# CW32L012 register map
Vendor: Wuhan Xinyuan Semiconductor Co.Ltd; Series: ARMCM0P; File version: 1.2
CPU: CM0+ r0p1, little endian, no MPU, no FPU, VTOR, 2 interrupt priority bits
Registers are 32-bit, read-write, no defined reset value unless marked. A register's access mark holds for its fields unless they carry their own. Offsets are from the block's base; [hi:lo] are bit positions; {n}, {i} and the like mark numbered series.

## BTIM1 — Base Timer 1
Base 0x40004800
Same registers: BTIM2 0x40004840, BTIM3 0x40004880
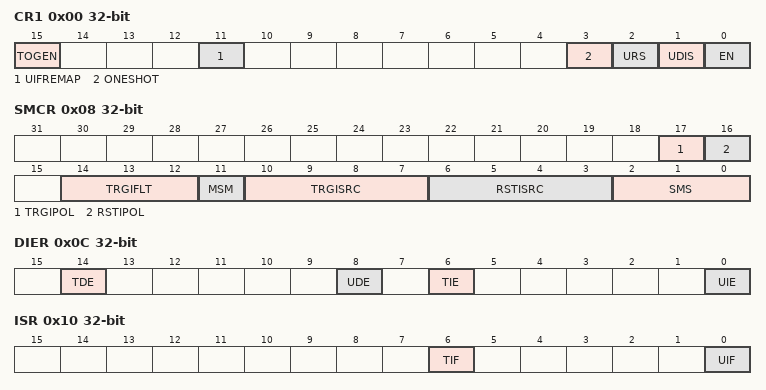
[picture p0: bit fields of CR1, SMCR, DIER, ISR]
0x00 CR1 — Control register1
  [15] TOGEN, [11] UIFREMAP, [3] ONESHOT, [2] URS, [1] UDIS, [0] EN
0x04 CR2 — Control register2
  [6:4] MMS
0x08 SMCR — Slave Mode Control register
  [17] TRGIPOL, [16] RSTIPOL, [14:12] TRGIFLT, [11] MSM, [10:7] TRGISRC, [6:3] RSTISRC, [2:0] SMS
0x0C DIER — Interrupt enable register
  [14] TDE, [8] UDE, [6] TIE, [0] UIE
0x10 ISR ro — Interrupt status register
  [6] TIF, [0] UIF
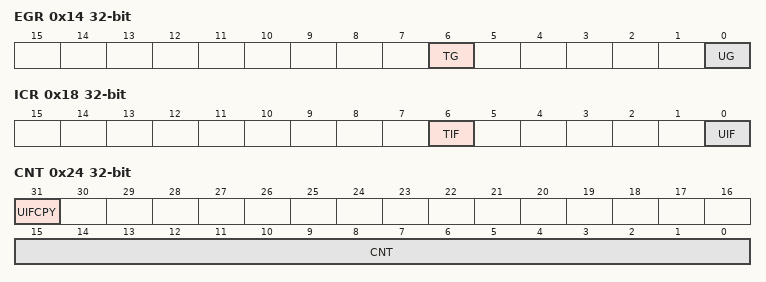
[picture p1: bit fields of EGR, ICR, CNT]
0x14 EGR wo — Event Generate register
  [6] TG, [0] UG
0x18 ICR — Interrupt flag clear register
  [6] TIF, [0] UIF
0x24 CNT — Counter Register
  [31] UIFCPY ro, [15:0] CNT
0x28 PSC — Prescaler Control Register
  [15:0] PSC
0x2C ARR — Auto Reload Register
  [15:0] ARR

## CORDIC
Base 0x40023400
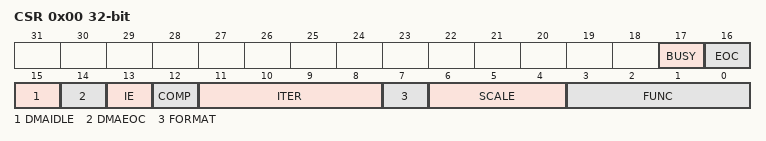
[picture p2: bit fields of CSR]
0x00 CSR — Control and State register
  [17] BUSY ro, [16] EOC ro, [15] DMAIDLE, [14] DMAEOC, [13] IE, [12] COMP, [11:8] ITER, [7] FORMAT, [6:4] SCALE, [3:0] FUNC
0x04 X — Data register X
0x08 Y — Data register Y
0x0C Z

## CRC
Base 0x40023000
0x00 CR — Control register
  [3:0] MODE
0x08 DR — Data register
  [7:0] DR
0x0C RESULT ro
  [15:0] RESULT

## DAC
Base 0x400000C0
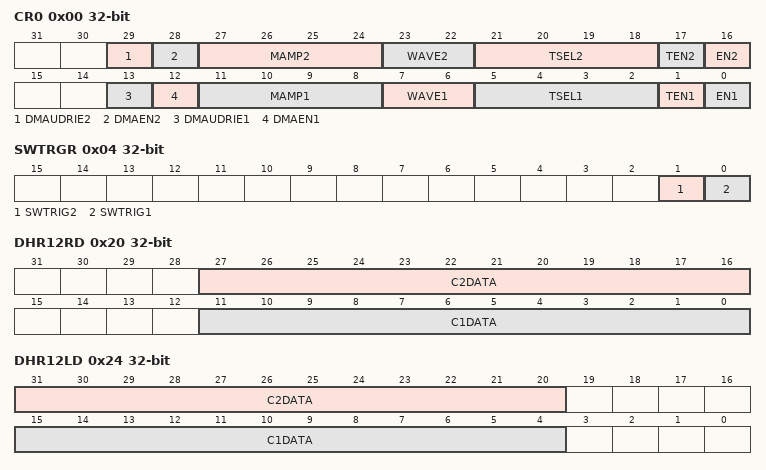
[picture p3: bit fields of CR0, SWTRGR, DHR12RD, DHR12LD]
0x00 CR0 — Control register
  [29] DMAUDRIE2, [28] DMAEN2, [27:24] MAMP2, [23:22] WAVE2, [21:18] TSEL2, [17] TEN2, [16] EN2, [13] DMAUDRIE1, [12] DMAEN1, [11:8] MAMP1, [7:6] WAVE1, [5:2] TSEL1, [1] TEN1, [0] EN1
0x04 SWTRGR — Data register
  [1] SWTRIG2, [0] SWTRIG1
0x08 DHR12R1
  [11:0] DATA
0x0C DHR12L1
  [15:4] DATA
0x10 DHR8R1
  [7:0] DATA
0x14 DHR12R2
  [11:0] DATA
0x18 DHR12L2
  [15:4] DATA
0x1C DHR8R2
  [7:0] DATA
0x20 DHR12RD
  [27:16] C2DATA, [11:0] C1DATA
0x24 DHR12LD
  [31:20] C2DATA, [15:4] C1DATA
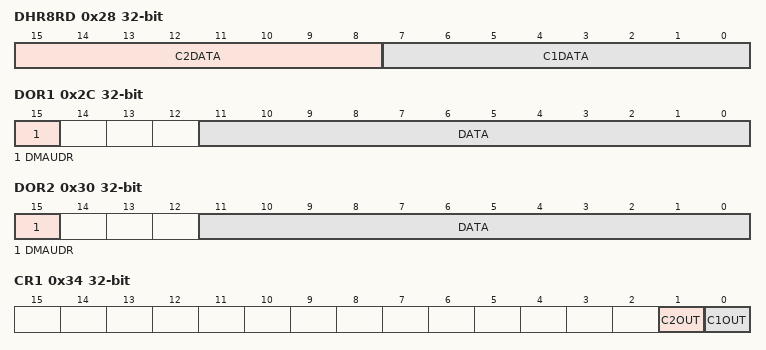
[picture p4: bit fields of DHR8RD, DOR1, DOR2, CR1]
0x28 DHR8RD
  [15:8] C2DATA, [7:0] C1DATA
0x2C DOR1
  [15] DMAUDR, [11:0] DATA ro
0x30 DOR2
  [15] DMAUDR, [11:0] DATA ro
0x34 CR1 — Result register
  [1] C2OUT, [0] C1OUT

## DMA
Base 0x40020000
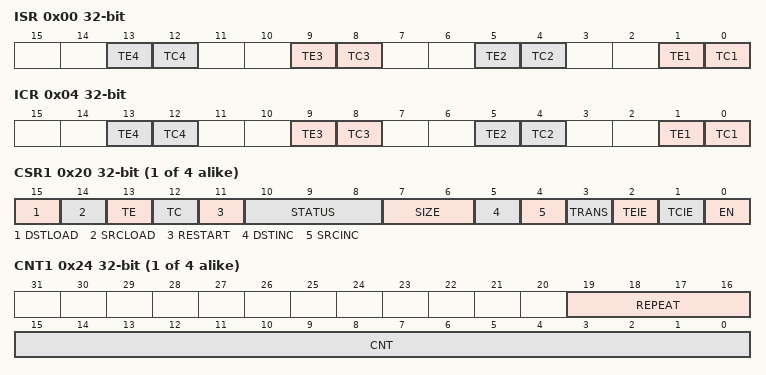
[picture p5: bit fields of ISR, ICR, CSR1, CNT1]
0x00 ISR ro — Interrupt status register
  [4n-3] TE{n} (n=1..4), [4n-4] TC{n} (n=1..4)
0x04 ICR — Interrupt flag clear register
  [4n-3] TE{n} (n=1..4), [4n-4] TC{n} (n=1..4)
{0x0+0x20*i} CSR{i} (i=1..4) — Channel1 control and status register
  [15] DSTLOAD, [14] SRCLOAD, [13] TE ro, [12] TC ro, [11] RESTART, [10:8] STATUS, [7:6] SIZE, [5] DSTINC, [4] SRCINC, [3] TRANS, [2] TEIE, [1] TCIE, [0] EN
{0x4+0x20*i} CNT{i} (i=1..4) — Channel1 counter register
  [19:16] REPEAT, [15:0] CNT
{0x8+0x20*i} SRCADDR{i} (i=1..4) — Channel1 source address register
  [31:0] SRCADDR
{0xC+0x20*i} DSTADDR{i} (i=1..4) — Channel1 destination address register
  [31:0] DSTADDR
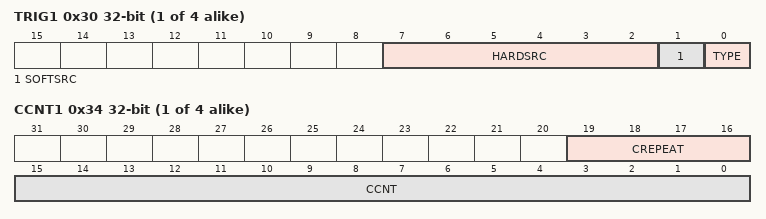
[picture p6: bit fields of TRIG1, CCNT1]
{0x10+0x20*i} TRIG{i} (i=1..4) — Channel1 trigger register
  [7:2] HARDSRC, [1] SOFTSRC, [0] TYPE
{0x14+0x20*i} CCNT{i} (i=1..4) — Channel1 trigger register
  [19:16] CREPEAT, [15:0] CCNT
{0x18+0x20*i} CSRCADDR{i} ro (i=1..4) — Channel1 source address register
  [31:0] CSRCADDR
{0x1C+0x20*i} CDSTADDR{i} ro (i=1..4) — Channel1 destination address register
  [31:0] CDSTADDR

## DMACHANNEL1
Base 0x40020020; alternate view of DMA
Same registers: DMACHANNEL2 0x40020040, DMACHANNEL3 0x40020060, DMACHANNEL4 0x40020080
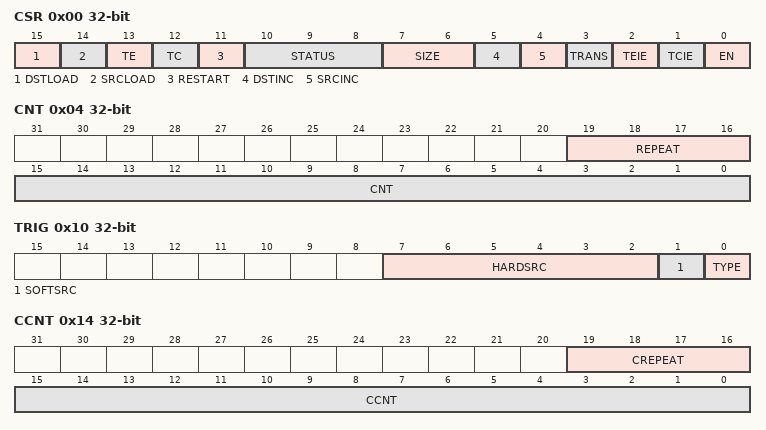
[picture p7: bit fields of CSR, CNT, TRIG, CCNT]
0x00 CSR — Channel1 control and status register
  [15] DSTLOAD, [14] SRCLOAD, [13] TE ro, [12] TC ro, [11] RESTART, [10:8] STATUS, [7:6] SIZE, [5] DSTINC, [4] SRCINC, [3] TRANS, [2] TEIE, [1] TCIE, [0] EN
0x04 CNT — Channel1 counter register
  [19:16] REPEAT, [15:0] CNT
0x08 SRCADDR — Channel1 source address register
0x0C DSTADDR — Channel1 destination address register
0x10 TRIG — Channel1 trigger register
  [7:2] HARDSRC, [1] SOFTSRC, [0] TYPE
0x14 CCNT — Channel1 trigger register
  [19:16] CREPEAT, [15:0] CCNT
0x18 CSRCADDR ro — Channel1 source address register
0x1C CDSTADDR ro — Channel1 destination address register
